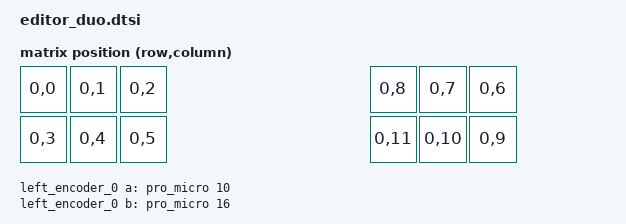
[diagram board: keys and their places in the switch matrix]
/* Generated by ZMK Editor from editor_duo.editor.json. */

#include <dt-bindings/zmk/matrix_transform.h>
#include <physical_layouts.dtsi>

/ {
    chosen {
        zmk,kscan = &kscan0;
        zmk,physical-layout = &editor_duo_layout;
    };

    kscan0: kscan {
        compatible = "zmk,kscan-gpio-direct";
        wakeup-source;
    };

    default_transform: keymap_transform_0 {
        compatible = "zmk,matrix-transform";
        rows = <1>;
        columns = <12>;
        map = <
RC(0,0)  RC(0,1)  RC(0,2)  RC(0,8)  RC(0,7)  RC(0,6)
RC(0,3)  RC(0,4)  RC(0,5)  RC(0,11) RC(0,10) RC(0,9)
        >;
    };

    left_encoder_0: encoder_left_0 {
        compatible = "alps,ec11";
        a-gpios = <&pro_micro 10 (GPIO_ACTIVE_HIGH | GPIO_PULL_UP)>;
        b-gpios = <&pro_micro 16 (GPIO_ACTIVE_HIGH | GPIO_PULL_UP)>;
        steps = <80>;
        status = "disabled";
    };

    sensors: sensors {
        compatible = "zmk,keymap-sensors";
        sensors = <&left_encoder_0>;
        triggers-per-rotation = <20>;
    };

    editor_duo_layout: editor_duo_layout {
        compatible = "zmk,physical-layout";
        display-name = "Editor Duo";
        transform = <&default_transform>;

        keys  //                     w   h    x    y     rot   rx   ry
            = <&key_physical_attrs 100 100    0    0      0    0    0>
            , <&key_physical_attrs 100 100  100    0      0    0    0>
            , <&key_physical_attrs 100 100  200    0      0    0    0>
            , <&key_physical_attrs 100 100  700    0      0    0    0>
            , <&key_physical_attrs 100 100  800    0      0    0    0>
            , <&key_physical_attrs 100 100  900    0      0    0    0>
            , <&key_physical_attrs 100 100    0  100      0    0    0>
            , <&key_physical_attrs 100 100  100  100      0    0    0>
            , <&key_physical_attrs 100 100  200  100      0    0    0>
            , <&key_physical_attrs 100 100  700  100      0    0    0>
            , <&key_physical_attrs 100 100  800  100      0    0    0>
            , <&key_physical_attrs 100 100  900  100      0    0    0>
            ;
    };
};
